# Cortex_M0+ register map
Vendor: ARM Ltd.; Series: M; File version: 2020-08-22T15:13:24.354567-05:00
Cortex-M0+ core descriptions, generated from ARM Development studio
CPU: CM4 r0p0, little endian, vendor SysTick, 8 interrupt priority bits
Registers are 32-bit, read-write, no defined reset value unless marked. A register's access mark holds for its fields unless they carry their own. Offsets are from the block's base; lines under a group give offsets from that group; [hi:lo] are bit positions; {n}, {i} and the like mark numbered series; 'fields as' and 'values as' point back to an identical list; <NAME> marks a mode.

## Memory map
0xE000E010 SysTick size 0x10 — System Timer registers
0xE000E100 NVIC blocks up to offset 0x320 — Nested Vectored Interrupt Controller registers
0xE000ED00 ID size 0x4 — ID registers
0xE000ED04 Control blocks up to offset 0x24 — System Control registers
0xE000ED90 MPU size 0x14 — Memory Protection Unit registers

## SysTick — System Timer registers
Base 0xE000E010
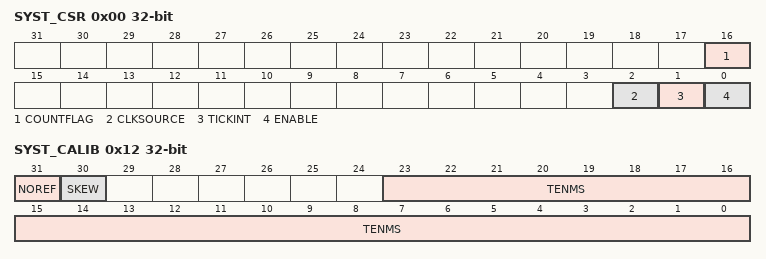
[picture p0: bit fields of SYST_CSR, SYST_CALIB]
0x00 SYST_CSR — Controls the system timer and provides status data
  [16] COUNTFLAG — Indicates whether the counter has counted to 0 since the last read of this register
    0=Not_counted_to_0; 1=Counted_to_0
  [2] CLKSOURCE — Indicates the SysTick clock source
    0=External_clock; 1=Processor_clock
  [1] TICKINT — Indicates whether counting to 0 causes the status of the SysTick exception to change to pending
    0=Does_not_affect_exception_status; 1=Changes_exception_status
  [0] ENABLE — Indicates the enabled status of the SysTick counter
    0=Counter_disabled; 1=Counter_operating
0x04 SYST_RVR — Sets or reads the reload value of the SYST_CVR register
  [23:0] RELOAD — The value to load into the SYST_CVR register when the counter reaches 0
0x08 SYST_CVR — Reads or clears the current counter value
  [23:0] CURRENT — This is the value of the counter at the time it is sampled
0x12 SYST_CALIB — Reads the calibration value and parameters for SysTick
  [31] NOREF — Indicates whether the IMPLEMENTATION DEFINED reference clock is provided
    0=Implemented; 1=Not_implemented
  [30] SKEW — Indicates whether the 10ms calibration value is exact
    0=Exact; 1=Inexact
  [23:0] TENMS — Optionally, holds a reload value to be used for 10ms (100Hz) timing, subject to system clock skew errors

## Control — System Control registers
Base 0xE000ED04
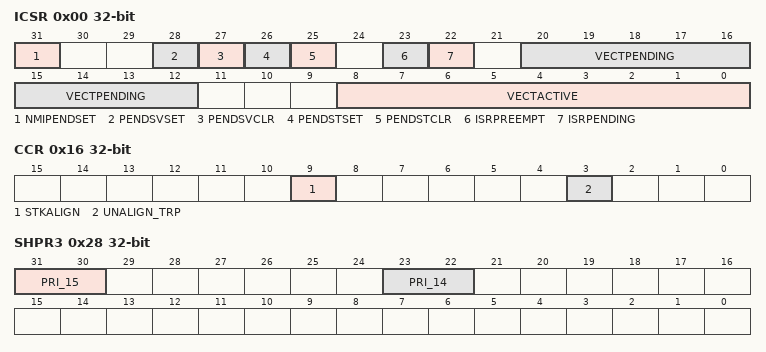
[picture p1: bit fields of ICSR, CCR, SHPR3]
0x00 ICSR — Controls and provides status information
  [31] NMIPENDSET — Activates an NMI exception or reads back the current state
    0=Do_not_activate; 1=Activate_NMI_exception
  [28] PENDSVSET — Sets a pending PendSV interrupt or reads back the current state
    0=Do_not_set; 1=Set_pending
  [27] PENDSVCLR — Clears a pending PendSV interrupt
    0=Do_not_clear; 1=Clear_pending
  [26] PENDSTSET — Sets a pending SysTick or reads back the current state
    0=Do_not_set; 1=Set_pending
  [25] PENDSTCLR — Clears a pending SysTick, whether set here or by the timer hardware
    0=Do_not_clear; 1=Clear_pending
  [23] ISRPREEMPT — Indicates whether a pending exception will be serviced on exit from debug halt state
    0=Will_not_service; 1=Will_service_pending_exception
  [22] ISRPENDING — Indicates if an external configurable, NVIC generated, interrupt is pending
    0=Interrupt_not_pending; 1=Interrupt_pending
  [20:12] VECTPENDING — The exception number for the highest priority pending exception. 0 indicates no pending exceptions
  [8:0] VECTACTIVE — The exception number for the current executing exception
0x04 VTOR — Holds the vector table offset address
  [29] TBLBASE — Determines whether the vector table is in the code or SRAM memory region
    0=CODE; 1=SRAM
  [31:7] TBLOFF — Bits [31:7] of the vector table address
0x08 AIRCR — Sets or returns interrupt control data
  [31:16] VECTKEY — Vector Key
  [31:16] VECTKEYSTAT
  [15] ENDIANNESS — Indicates the memory system data endianness
    0=Little_endian; 1=Big_endian
  [2] SYSRESETREQ — System Reset Request
    0=Do_not_request_reset; 1=Request_reset
  [1] VECTCLRACTIVE — Clears all active state information for fixed and configurable exceptions
    0=Do_not_clear; 1=Clear_state_information
0x16 CCR ro — Returns configuration and control data
  [9] STKALIGN — On exception entry, the SP used prior to the exception is adjusted to be 8-byte aligned and the context to restore it is saved. The SP is restored on the associated exception return
  [3] UNALIGN_TRP — Unaligned word and halfword accesses generate a HardFault exception
0x24 SHPR2 — Sets or returns priority for system handler 11
  [31:30] PRI_11 — Priority of system handler 11, SVCall
0x28 SHPR3 — Sets or returns priority for system handlers 14-15
  [31:30] PRI_15 — Priority of system handler 15, SysTick
  [23:22] PRI_14 — Priority of system handler 14, PendSV
0x32 SHCSR — Controls and provides the status of system handlers
  [15] SVCALLPENDED — This bit reflects the pending state on a read, and updates the pending state, to the value written, on a write
    0=Not_pending; 1=Pending
